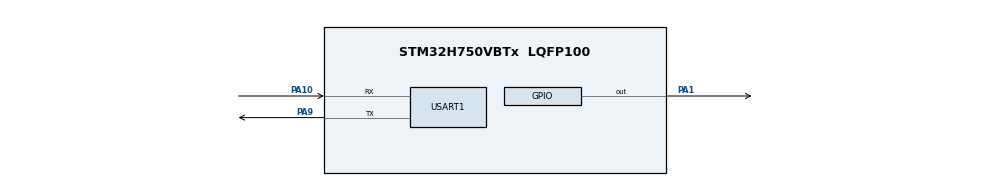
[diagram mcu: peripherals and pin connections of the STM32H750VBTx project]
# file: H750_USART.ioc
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CORTEX_M7.AccessPermission_Spec=MPU_REGION_FULL_ACCESS
CORTEX_M7.BaseAddress_Spec=0x24000000
CORTEX_M7.CPU_DCache=Enabled
CORTEX_M7.CPU_ICache=Enabled
CORTEX_M7.DisableExec_Spec=MPU_INSTRUCTION_ACCESS_ENABLE
CORTEX_M7.IsBufferable_Spec=MPU_ACCESS_BUFFERABLE
CORTEX_M7.IsCacheable_Spec=MPU_ACCESS_CACHEABLE
CORTEX_M7.IsShareable_Spec=MPU_ACCESS_NOT_SHAREABLE
CORTEX_M7.Size_Spec=MPU_REGION_SIZE_512KB
CORTEX_M7.SubRegionDisable_Spec=0x00
CORTEX_M7.TypeExtField_Spec=MPU_TEX_LEVEL1
CORTEX_M7.default_mode_Activation=1
Mcu.Family=STM32H7
Mcu.Name=STM32H750VBTx
Mcu.Package=LQFP100
NVIC.PriorityGroup=NVIC_PRIORITYGROUP_4
NVIC.USART1_IRQn=true\:0\:0\:false\:false\:true\:true\:true\:true
PA1.GPIO_Speed=GPIO_SPEED_FREQ_MEDIUM
PA1.Signal=GPIO_Output
PA10.Mode=Asynchronous
PA10.Signal=USART1_RX
PA9.Mode=Asynchronous
PA9.Signal=USART1_TX
PH0-OSC_IN\ (PH0).Mode=HSE-External-Oscillator
PH0-OSC_IN\ (PH0).Signal=RCC_OSC_IN
PH1-OSC_OUT\ (PH1).Mode=HSE-External-Oscillator
PH1-OSC_OUT\ (PH1).Signal=RCC_OSC_OUT
ProjectManager.HeapSize=0x400
ProjectManager.StackSize=0x400
ProjectManager.TargetToolchain=MDK-ARM V5
RCC.ADCFreq_Value=16125000
RCC.APB1Freq_Value=120000000
RCC.APB2Freq_Value=120000000
RCC.APB3Freq_Value=120000000
RCC.APB4Freq_Value=120000000
RCC.CortexFreq_Value=480000000
RCC.D1PPRE=RCC_APB3_DIV2
RCC.D2PPRE1=RCC_APB1_DIV2
RCC.D2PPRE2=RCC_APB2_DIV2
RCC.D3PPRE=RCC_APB4_DIV2
RCC.DIVM1=2
RCC.DIVN1=240
RCC.HCLKFreq_Value=240000000
RCC.HPRE=RCC_HCLK_DIV2
RCC.HSE_VALUE=8000000
RCC.PLLSourceVirtual=RCC_PLLSOURCE_HSE
RCC.PWR_Regulator_Voltage_Scale=PWR_REGULATOR_VOLTAGE_SCALE0
RCC.ProductRev=revV
RCC.SYSCLKFreq_VALUE=480000000
RCC.SYSCLKSource=RCC_SYSCLKSOURCE_PLLCLK
RCC.USBFreq_Value=480000000
USART1.VirtualMode-Asynchronous=VM_ASYNC
board=custom

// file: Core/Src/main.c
/* USER CODE BEGIN Header */
/**
  ******************************************************************************
  * @file           : main.c
  * @brief          : Main program body
  ******************************************************************************
  * @attention
  *
  * Copyright (c) 2024 STMicroelectronics.
  * All rights reserved.
  *
  * This software is licensed under terms that can be found in the LICENSE file
  * in the root directory of this software component.
  * If no LICENSE file comes with this software, it is provided AS-IS.
  *
  ******************************************************************************
  */
/* USER CODE END Header */
#include "main.h"
#include "usart.h"
#include "gpio.h"

/* USER CODE BEGIN Includes */
#include "stdio.h"//对printf进行重定向
#include <stdint.h>
/**
  * 函数功能: 重定向c库函数printf到DEBUG_USARTx
  * 输入参数: 无
  * 返 回 值: 无
  * 说    明：无
  */
int fputc(int ch, FILE *f)
{
  HAL_UART_Transmit(&huart1, (uint8_t *)&ch, 1, 0xffff);
  return ch;
}

/**
  * 函数功能: 重定向c库函数getchar,scanf到DEBUG_USARTx
  * 输入参数: 无
  * 返 回 值: 无
  * 说    明：无
  */
int fgetc(FILE *f)
{
  uint8_t ch = 0;
  HAL_UART_Receive(&huart1, &ch, 1, 0xffff);
  return ch;
}
/* USER CODE END Includes */

void SystemClock_Config(void);
static void MPU_Config(void);

int main(void)
{

  /* MPU Configuration--------------------------------------------------------*/
  MPU_Config();

  /* Enable I-Cache---------------------------------------------------------*/
  SCB_EnableICache();

  /* Enable D-Cache---------------------------------------------------------*/
  SCB_EnableDCache();

  /* MCU Configuration--------------------------------------------------------*/

  /* Reset of all peripherals, Initializes the Flash interface and the Systick. */
  HAL_Init();

  /* Configure the system clock */
  SystemClock_Config();

  /* Initialize all configured peripherals */
  MX_GPIO_Init();
  MX_USART1_UART_Init();

  /* Infinite loop */
  while (1)
  {

    /* USER CODE BEGIN 3 */
		HAL_GPIO_WritePin(GPIO_LED_PORT, GPIO_LED_PIN, GPIO_PIN_SET);
		HAL_Delay(200);
		HAL_GPIO_WritePin(GPIO_LED_PORT, GPIO_LED_PIN, GPIO_PIN_RESET);
		HAL_Delay(200);
  	printf("hello\r\n");
  }
  /* USER CODE END 3 */
}

void SystemClock_Config(void)
{
  RCC_OscInitTypeDef RCC_OscInitStruct = {0};
  RCC_ClkInitTypeDef RCC_ClkInitStruct = {0};

  /** Supply configuration update enable
  */
  HAL_PWREx_ConfigSupply(PWR_LDO_SUPPLY);

  /** Configure the main internal regulator output voltage
  */
  __HAL_PWR_VOLTAGESCALING_CONFIG(PWR_REGULATOR_VOLTAGE_SCALE0);

  while(!__HAL_PWR_GET_FLAG(PWR_FLAG_VOSRDY)) {}

  /** Initializes the RCC Oscillators according to the specified parameters
  * in the RCC_OscInitTypeDef structure.
  */
  RCC_OscInitStruct.OscillatorType = RCC_OSCILLATORTYPE_HSE;
  RCC_OscInitStruct.HSEState = RCC_HSE_ON;
  RCC_OscInitStruct.PLL.PLLState = RCC_PLL_ON;
  RCC_OscInitStruct.PLL.PLLSource = RCC_PLLSOURCE_HSE;
  RCC_OscInitStruct.PLL.PLLM = 2;
  RCC_OscInitStruct.PLL.PLLN = 240;
  RCC_OscInitStruct.PLL.PLLP = 2;
  RCC_OscInitStruct.PLL.PLLQ = 2;
  RCC_OscInitStruct.PLL.PLLR = 2;
  RCC_OscInitStruct.PLL.PLLRGE = RCC_PLL1VCIRANGE_2;
  RCC_OscInitStruct.PLL.PLLVCOSEL = RCC_PLL1VCOWIDE;
  RCC_OscInitStruct.PLL.PLLFRACN = 0;
  if (HAL_RCC_OscConfig(&RCC_OscInitStruct) != HAL_OK)
  {
    Error_Handler();
  }

  /** Initializes the CPU, AHB and APB buses clocks
  */
  RCC_ClkInitStruct.ClockType = RCC_CLOCKTYPE_HCLK|RCC_CLOCKTYPE_SYSCLK
                              |RCC_CLOCKTYPE_PCLK1|RCC_CLOCKTYPE_PCLK2
                              |RCC_CLOCKTYPE_D3PCLK1|RCC_CLOCKTYPE_D1PCLK1;
  RCC_ClkInitStruct.SYSCLKSource = RCC_SYSCLKSOURCE_PLLCLK;
  RCC_ClkInitStruct.SYSCLKDivider = RCC_SYSCLK_DIV1;
  RCC_ClkInitStruct.AHBCLKDivider = RCC_HCLK_DIV2;
  RCC_ClkInitStruct.APB3CLKDivider = RCC_APB3_DIV2;
  RCC_ClkInitStruct.APB1CLKDivider = RCC_APB1_DIV2;
  RCC_ClkInitStruct.APB2CLKDivider = RCC_APB2_DIV2;
  RCC_ClkInitStruct.APB4CLKDivider = RCC_APB4_DIV2;

  if (HAL_RCC_ClockConfig(&RCC_ClkInitStruct, FLASH_LATENCY_4) != HAL_OK)
  {
    Error_Handler();
  }
}

/* MPU Configuration */

void MPU_Config(void)
{
  MPU_Region_InitTypeDef MPU_InitStruct = {0};

  /* Disables the MPU */
  HAL_MPU_Disable();

  /** Initializes and configures the Region and the memory to be protected
  */
  MPU_InitStruct.Enable = MPU_REGION_ENABLE;
  MPU_InitStruct.Number = MPU_REGION_NUMBER0;
  MPU_InitStruct.BaseAddress = 0x24000000;
  MPU_InitStruct.Size = MPU_REGION_SIZE_512KB;
  MPU_InitStruct.SubRegionDisable = 0x00;
  MPU_InitStruct.TypeExtField = MPU_TEX_LEVEL1;
  MPU_InitStruct.AccessPermission = MPU_REGION_FULL_ACCESS;
  MPU_InitStruct.DisableExec = MPU_INSTRUCTION_ACCESS_ENABLE;
  MPU_InitStruct.IsShareable = MPU_ACCESS_NOT_SHAREABLE;
  MPU_InitStruct.IsCacheable = MPU_ACCESS_CACHEABLE;
  MPU_InitStruct.IsBufferable = MPU_ACCESS_BUFFERABLE;

  HAL_MPU_ConfigRegion(&MPU_InitStruct);
  /* Enables the MPU */
  HAL_MPU_Enable(MPU_PRIVILEGED_DEFAULT);

}

void Error_Handler(void)
{
  __disable_irq();
  while (1)
  {
  }
}
